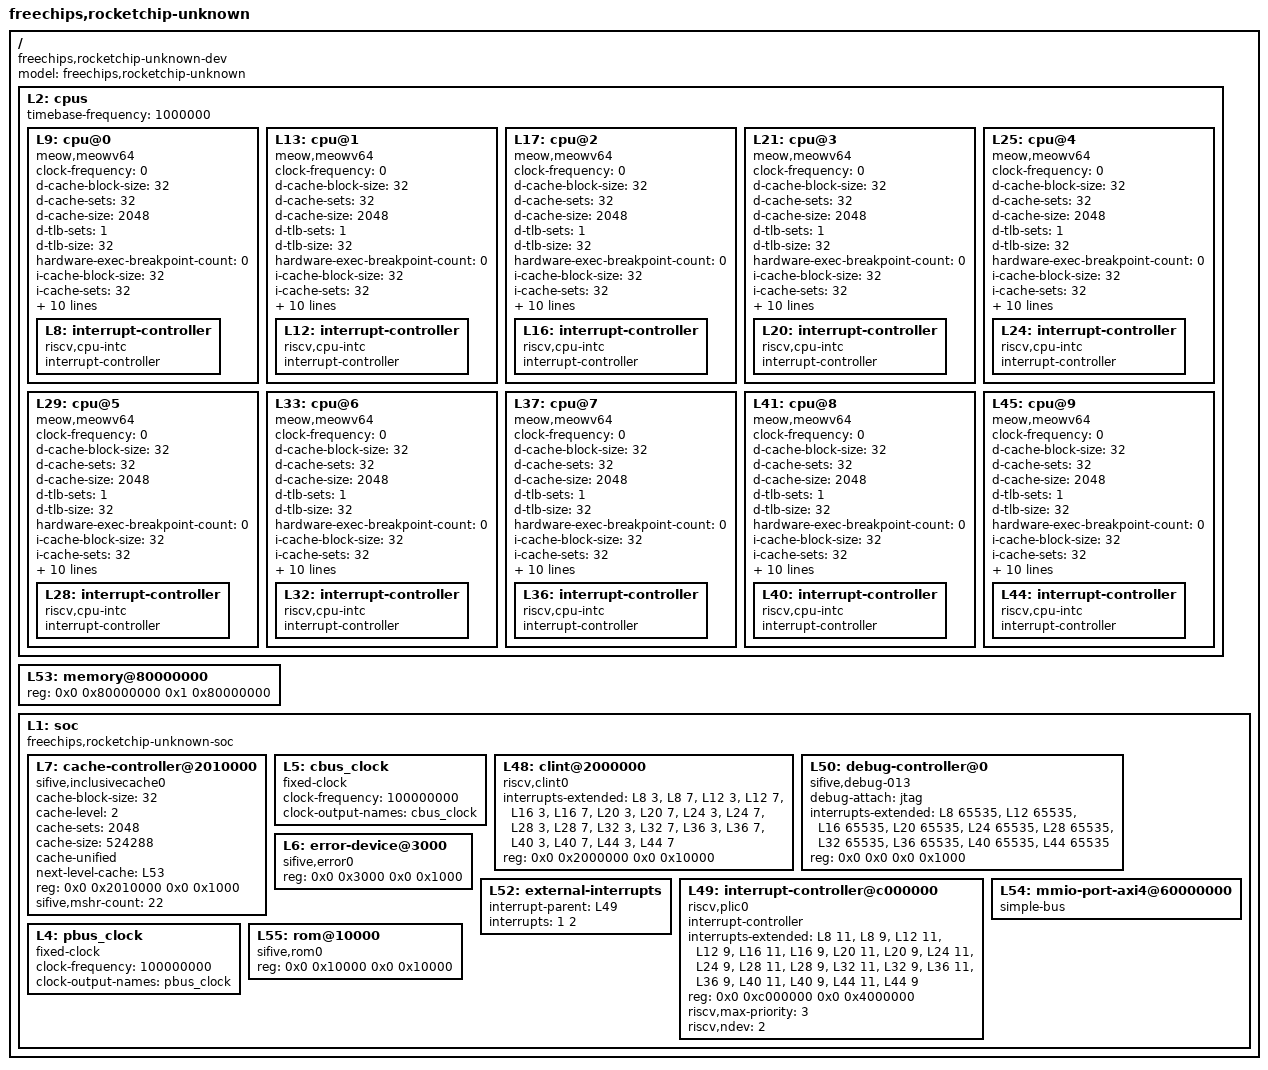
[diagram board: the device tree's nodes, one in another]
/dts-v1/;

/ {
	#address-cells = <2>;
	#size-cells = <2>;
	compatible = "freechips,rocketchip-unknown-dev";
	model = "freechips,rocketchip-unknown";
	L2: cpus {
		#address-cells = <1>;
		#size-cells = <0>;
		timebase-frequency = <1000000>;
		L9: cpu@0 {
			clock-frequency = <0>;
			compatible = "meow,meowv64", "riscv";
			d-cache-block-size = <32>;
			d-cache-sets = <32>;
			d-cache-size = <2048>;
			d-tlb-sets = <1>;
			d-tlb-size = <32>;
			device_type = "cpu";
			hardware-exec-breakpoint-count = <0>;
			i-cache-block-size = <32>;
			i-cache-sets = <32>;
			i-cache-size = <2048>;
			i-tlb-sets = <1>;
			i-tlb-size = <32>;
			mmu-type = "riscv,sv39";
			next-level-cache = <&L7>;
			reg = <0x0>;
			riscv,isa = "rv64imafdczicsr_zifencei_zihpm_zvl256b_zve64x";
			status = "okay";
			timebase-frequency = <1000000>;
			tlb-split;
			L8: interrupt-controller {
				#interrupt-cells = <1>;
				compatible = "riscv,cpu-intc";
				interrupt-controller;
			};
		};
		L13: cpu@1 {
			clock-frequency = <0>;
			compatible = "meow,meowv64", "riscv";
			d-cache-block-size = <32>;
			d-cache-sets = <32>;
			d-cache-size = <2048>;
			d-tlb-sets = <1>;
			d-tlb-size = <32>;
			device_type = "cpu";
			hardware-exec-breakpoint-count = <0>;
			i-cache-block-size = <32>;
			i-cache-sets = <32>;
			i-cache-size = <2048>;
			i-tlb-sets = <1>;
			i-tlb-size = <32>;
			mmu-type = "riscv,sv39";
			next-level-cache = <&L7>;
			reg = <0x1>;
			riscv,isa = "rv64imafdczicsr_zifencei_zihpm_zvl256b_zve64x";
			status = "okay";
			timebase-frequency = <1000000>;
			tlb-split;
			L12: interrupt-controller {
				#interrupt-cells = <1>;
				compatible = "riscv,cpu-intc";
				interrupt-controller;
			};
		};
		L17: cpu@2 {
			clock-frequency = <0>;
			compatible = "meow,meowv64", "riscv";
			d-cache-block-size = <32>;
			d-cache-sets = <32>;
			d-cache-size = <2048>;
			d-tlb-sets = <1>;
			d-tlb-size = <32>;
			device_type = "cpu";
			hardware-exec-breakpoint-count = <0>;
			i-cache-block-size = <32>;
			i-cache-sets = <32>;
			i-cache-size = <2048>;
			i-tlb-sets = <1>;
			i-tlb-size = <32>;
			mmu-type = "riscv,sv39";
			next-level-cache = <&L7>;
			reg = <0x2>;
			riscv,isa = "rv64imafdczicsr_zifencei_zihpm_zvl256b_zve64x";
			status = "okay";
			timebase-frequency = <1000000>;
			tlb-split;
			L16: interrupt-controller {
				#interrupt-cells = <1>;
				compatible = "riscv,cpu-intc";
				interrupt-controller;
			};
		};
		L21: cpu@3 {
			clock-frequency = <0>;
			compatible = "meow,meowv64", "riscv";
			d-cache-block-size = <32>;
			d-cache-sets = <32>;
			d-cache-size = <2048>;
			d-tlb-sets = <1>;
			d-tlb-size = <32>;
			device_type = "cpu";
			hardware-exec-breakpoint-count = <0>;
			i-cache-block-size = <32>;
			i-cache-sets = <32>;
			i-cache-size = <2048>;
			i-tlb-sets = <1>;
			i-tlb-size = <32>;
			mmu-type = "riscv,sv39";
			next-level-cache = <&L7>;
			reg = <0x3>;
			riscv,isa = "rv64imafdczicsr_zifencei_zihpm_zvl256b_zve64x";
			status = "okay";
			timebase-frequency = <1000000>;
			tlb-split;
			L20: interrupt-controller {
				#interrupt-cells = <1>;
				compatible = "riscv,cpu-intc";
				interrupt-controller;
			};
		};
		L25: cpu@4 {
			clock-frequency = <0>;
			compatible = "meow,meowv64", "riscv";
			d-cache-block-size = <32>;
			d-cache-sets = <32>;
			d-cache-size = <2048>;
			d-tlb-sets = <1>;
			d-tlb-size = <32>;
			device_type = "cpu";
			hardware-exec-breakpoint-count = <0>;
			i-cache-block-size = <32>;
			i-cache-sets = <32>;
			i-cache-size = <2048>;
			i-tlb-sets = <1>;
			i-tlb-size = <32>;
			mmu-type = "riscv,sv39";
			next-level-cache = <&L7>;
			reg = <0x4>;
			riscv,isa = "rv64imafdczicsr_zifencei_zihpm_zvl256b_zve64x";
			status = "okay";
			timebase-frequency = <1000000>;
			tlb-split;
			L24: interrupt-controller {
				#interrupt-cells = <1>;
				compatible = "riscv,cpu-intc";
				interrupt-controller;
			};
		};
		L29: cpu@5 {
			clock-frequency = <0>;
			compatible = "meow,meowv64", "riscv";
			d-cache-block-size = <32>;
			d-cache-sets = <32>;
			d-cache-size = <2048>;
			d-tlb-sets = <1>;
			d-tlb-size = <32>;
			device_type = "cpu";
			hardware-exec-breakpoint-count = <0>;
			i-cache-block-size = <32>;
			i-cache-sets = <32>;
			i-cache-size = <2048>;
			i-tlb-sets = <1>;
			i-tlb-size = <32>;
			mmu-type = "riscv,sv39";
			next-level-cache = <&L7>;
			reg = <0x5>;
			riscv,isa = "rv64imafdczicsr_zifencei_zihpm_zvl256b_zve64x";
			status = "okay";
			timebase-frequency = <1000000>;
			tlb-split;
			L28: interrupt-controller {
				#interrupt-cells = <1>;
				compatible = "riscv,cpu-intc";
				interrupt-controller;
			};
		};
		L33: cpu@6 {
			clock-frequency = <0>;
			compatible = "meow,meowv64", "riscv";
			d-cache-block-size = <32>;
			d-cache-sets = <32>;
			d-cache-size = <2048>;
			d-tlb-sets = <1>;
			d-tlb-size = <32>;
			device_type = "cpu";
			hardware-exec-breakpoint-count = <0>;
			i-cache-block-size = <32>;
			i-cache-sets = <32>;
			i-cache-size = <2048>;
			i-tlb-sets = <1>;
			i-tlb-size = <32>;
			mmu-type = "riscv,sv39";
			next-level-cache = <&L7>;
			reg = <0x6>;
			riscv,isa = "rv64imafdczicsr_zifencei_zihpm_zvl256b_zve64x";
			status = "okay";
			timebase-frequency = <1000000>;
			tlb-split;
			L32: interrupt-controller {
				#interrupt-cells = <1>;
				compatible = "riscv,cpu-intc";
				interrupt-controller;
			};
		};
		L37: cpu@7 {
			clock-frequency = <0>;
			compatible = "meow,meowv64", "riscv";
			d-cache-block-size = <32>;
			d-cache-sets = <32>;
			d-cache-size = <2048>;
			d-tlb-sets = <1>;
			d-tlb-size = <32>;
			device_type = "cpu";
			hardware-exec-breakpoint-count = <0>;
			i-cache-block-size = <32>;
			i-cache-sets = <32>;
			i-cache-size = <2048>;
			i-tlb-sets = <1>;
			i-tlb-size = <32>;
			mmu-type = "riscv,sv39";
			next-level-cache = <&L7>;
			reg = <0x7>;
			riscv,isa = "rv64imafdczicsr_zifencei_zihpm_zvl256b_zve64x";
			status = "okay";
			timebase-frequency = <1000000>;
			tlb-split;
			L36: interrupt-controller {
				#interrupt-cells = <1>;
				compatible = "riscv,cpu-intc";
				interrupt-controller;
			};
		};
		L41: cpu@8 {
			clock-frequency = <0>;
			compatible = "meow,meowv64", "riscv";
			d-cache-block-size = <32>;
			d-cache-sets = <32>;
			d-cache-size = <2048>;
			d-tlb-sets = <1>;
			d-tlb-size = <32>;
			device_type = "cpu";
			hardware-exec-breakpoint-count = <0>;
			i-cache-block-size = <32>;
			i-cache-sets = <32>;
			i-cache-size = <2048>;
			i-tlb-sets = <1>;
			i-tlb-size = <32>;
			mmu-type = "riscv,sv39";
			next-level-cache = <&L7>;
			reg = <0x8>;
			riscv,isa = "rv64imafdczicsr_zifencei_zihpm_zvl256b_zve64x";
			status = "okay";
			timebase-frequency = <1000000>;
			tlb-split;
			L40: interrupt-controller {
				#interrupt-cells = <1>;
				compatible = "riscv,cpu-intc";
				interrupt-controller;
			};
		};
		L45: cpu@9 {
			clock-frequency = <0>;
			compatible = "meow,meowv64", "riscv";
			d-cache-block-size = <32>;
			d-cache-sets = <32>;
			d-cache-size = <2048>;
			d-tlb-sets = <1>;
			d-tlb-size = <32>;
			device_type = "cpu";
			hardware-exec-breakpoint-count = <0>;
			i-cache-block-size = <32>;
			i-cache-sets = <32>;
			i-cache-size = <2048>;
			i-tlb-sets = <1>;
			i-tlb-size = <32>;
			mmu-type = "riscv,sv39";
			next-level-cache = <&L7>;
			reg = <0x9>;
			riscv,isa = "rv64imafdczicsr_zifencei_zihpm_zvl256b_zve64x";
			status = "okay";
			timebase-frequency = <1000000>;
			tlb-split;
			L44: interrupt-controller {
				#interrupt-cells = <1>;
				compatible = "riscv,cpu-intc";
				interrupt-controller;
			};
		};
	};
	L53: memory@80000000 {
		device_type = "memory";
		reg = <0x0 0x80000000 0x1 0x80000000>;
	};
	L1: soc {
		#address-cells = <2>;
		#size-cells = <2>;
		compatible = "freechips,rocketchip-unknown-soc", "simple-bus";
		ranges;
		L7: cache-controller@2010000 {
			cache-block-size = <32>;
			cache-level = <2>;
			cache-sets = <2048>;
			cache-size = <524288>;
			cache-unified;
			compatible = "sifive,inclusivecache0", "cache";
			next-level-cache = <&L53>;
			reg = <0x0 0x2010000 0x0 0x1000>;
			reg-names = "control";
			sifive,mshr-count = <22>;
		};
		L5: cbus_clock {
			#clock-cells = <0>;
			clock-frequency = <100000000>;
			clock-output-names = "cbus_clock";
			compatible = "fixed-clock";
		};
		L48: clint@2000000 {
			compatible = "riscv,clint0";
			interrupts-extended = <&L8 3 &L8 7 &L12 3 &L12 7 &L16 3 &L16 7 &L20 3 &L20 7 &L24 3 &L24 7 &L28 3 &L28 7 &L32 3 &L32 7 &L36 3 &L36 7 &L40 3 &L40 7 &L44 3 &L44 7>;
			reg = <0x0 0x2000000 0x0 0x10000>;
			reg-names = "control";
		};
		L50: debug-controller@0 {
			compatible = "sifive,debug-013", "riscv,debug-013";
			debug-attach = "jtag";
			interrupts-extended = <&L8 65535 &L12 65535 &L16 65535 &L20 65535 &L24 65535 &L28 65535 &L32 65535 &L36 65535 &L40 65535 &L44 65535>;
			reg = <0x0 0x0 0x0 0x1000>;
			reg-names = "control";
		};
		L6: error-device@3000 {
			compatible = "sifive,error0";
			reg = <0x0 0x3000 0x0 0x1000>;
		};
		L52: external-interrupts {
			interrupt-parent = <&L49>;
			interrupts = <1 2>;
		};
		L49: interrupt-controller@c000000 {
			#interrupt-cells = <1>;
			compatible = "riscv,plic0";
			interrupt-controller;
			interrupts-extended = <&L8 11 &L8 9 &L12 11 &L12 9 &L16 11 &L16 9 &L20 11 &L20 9 &L24 11 &L24 9 &L28 11 &L28 9 &L32 11 &L32 9 &L36 11 &L36 9 &L40 11 &L40 9 &L44 11 &L44 9>;
			reg = <0x0 0xc000000 0x0 0x4000000>;
			reg-names = "control";
			riscv,max-priority = <3>;
			riscv,ndev = <2>;
		};
		L54: mmio-port-axi4@60000000 {
			#address-cells = <2>;
			#size-cells = <1>;
			compatible = "simple-bus";
			ranges = <0x0 0x60000000 0x0 0x60000000 0x20000000 0x2 0x0 0x2 0x0 0x0>;
		};
		L4: pbus_clock {
			#clock-cells = <0>;
			clock-frequency = <100000000>;
			clock-output-names = "pbus_clock";
			compatible = "fixed-clock";
		};
		L55: rom@10000 {
			compatible = "sifive,rom0";
			reg = <0x0 0x10000 0x0 0x10000>;
			reg-names = "mem";
		};
	};
};
